# MIMXRT1021 register map
Vendor: nxp.com; File version: 1.0
CPU: CM7 r0p1, little endian, MPU, FPU, VTOR, 4 interrupt priority bits
Registers are 32-bit, read-write, reset 0x0 unless marked. A register's access mark holds for its fields unless they carry their own. Offsets are from the block's base; [hi:lo] are bit positions.

## IOMUXC (part 2 of 3)
Base 0x401F8000; register names take the prefix IOMUXC_
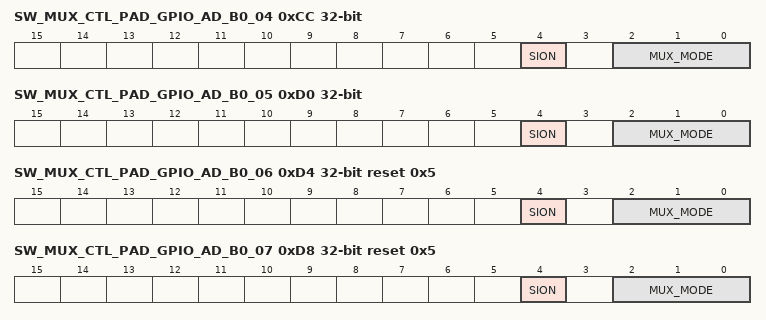
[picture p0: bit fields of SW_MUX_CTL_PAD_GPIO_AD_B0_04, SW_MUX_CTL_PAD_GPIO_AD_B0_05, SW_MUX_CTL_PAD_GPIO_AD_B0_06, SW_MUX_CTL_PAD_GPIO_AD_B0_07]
0xCC SW_MUX_CTL_PAD_GPIO_AD_B0_04 — SW_MUX_CTL_PAD_GPIO_AD_B0_04 SW MUX Control Register
  [4] SION — Software Input On Field.
    0=DISABLED (Input Path is determined by functionality); 1=ENABLED (Force input path of pad GPIO_AD_B0_04)
  [2:0] MUX_MODE — MUX Mode Select Field.
    0=ALT0 (Select mux mode: ALT0 mux port: JTAG_TDO of instance: jtag_mux); 1=ALT1 (Select mux mode: ALT1 mux port: FLEXCAN1_TX of instance: flexcan1); 2=ALT2 (Select mux mode: ALT2 mux port: USDHC1_WP of instance: usdhc1); 3=ALT3 (Select mux mode: ALT3 mux port: QTIMER2_TIMER0 of instance: qtimer2); 4=ALT4 (Select mux mode: ALT4 mux port: ENET_MDIO of instance: enet); 5=ALT5 (Select mux mode: ALT5 mux port: GPIO1_IO04 of instance: gpio1); 6=ALT6 (Select mux mode: ALT6 mux port: USB_OTG1_PWR of instance: usb); 7=ALT7 (Select mux mode: ALT7 mux port: EWM_OUT_B of instance: ewm)
0xD0 SW_MUX_CTL_PAD_GPIO_AD_B0_05 — SW_MUX_CTL_PAD_GPIO_AD_B0_05 SW MUX Control Register
  [4] SION — Software Input On Field.
    0=DISABLED (Input Path is determined by functionality); 1=ENABLED (Force input path of pad GPIO_AD_B0_05)
  [2:0] MUX_MODE — MUX Mode Select Field.
    0=ALT0 (Select mux mode: ALT0 mux port: JTAG_TRSTB of instance: jtag_mux); 1=ALT1 (Select mux mode: ALT1 mux port: FLEXCAN1_RX of instance: flexcan1); 2=ALT2 (Select mux mode: ALT2 mux port: USDHC1_CD_B of instance: usdhc1); 3=ALT3 (Select mux mode: ALT3 mux port: QTIMER2_TIMER1 of instance: qtimer2); 4=ALT4 (Select mux mode: ALT4 mux port: ENET_MDC of instance: enet); 5=ALT5 (Select mux mode: ALT5 mux port: GPIO1_IO05 of instance: gpio1); 6=ALT6 (Select mux mode: ALT6 mux port: USB_OTG1_ID of instance: anatop); 7=ALT7 (Select mux mode: ALT7 mux port: NMI_GLUE_NMI of instance: nmi_glue)
0xD4 SW_MUX_CTL_PAD_GPIO_AD_B0_06 reset 0x5 — SW_MUX_CTL_PAD_GPIO_AD_B0_06 SW MUX Control Register
  [4] SION — Software Input On Field.
    0=DISABLED (Input Path is determined by functionality); 1=ENABLED (Force input path of pad GPIO_AD_B0_06)
  [2:0] MUX_MODE — MUX Mode Select Field.
    0=ALT0 (Select mux mode: ALT0 mux port: PIT_TRIGGER00 of instance: pit); 1=ALT1 (Select mux mode: ALT1 mux port: MQS_RIGHT of instance: mqs); 2=ALT2 (Select mux mode: ALT2 mux port: LPUART1_TX of instance: lpuart1); 3=ALT3 (Select mux mode: ALT3 mux port: QTIMER2_TIMER2 of instance: qtimer2); 4=ALT4 (Select mux mode: ALT4 mux port: FLEXPWM2_PWMA03 of instance: flexpwm2); 5=ALT5 (Select mux mode: ALT5 mux port: GPIO1_IO06 of instance: gpio1); 6=ALT6 (Select mux mode: ALT6 mux port: REF_32K_OUT of instance: anatop)
0xD8 SW_MUX_CTL_PAD_GPIO_AD_B0_07 reset 0x5 — SW_MUX_CTL_PAD_GPIO_AD_B0_07 SW MUX Control Register
  [4] SION — Software Input On Field.
    0=DISABLED (Input Path is determined by functionality); 1=ENABLED (Force input path of pad GPIO_AD_B0_07)
  [2:0] MUX_MODE — MUX Mode Select Field.
    0=ALT0 (Select mux mode: ALT0 mux port: PIT_TRIGGER01 of instance: pit); 1=ALT1 (Select mux mode: ALT1 mux port: MQS_LEFT of instance: mqs); 2=ALT2 (Select mux mode: ALT2 mux port: LPUART1_RX of instance: lpuart1); 3=ALT3 (Select mux mode: ALT3 mux port: QTIMER2_TIMER3 of instance: qtimer2); 4=ALT4 (Select mux mode: ALT4 mux port: FLEXPWM2_PWMB03 of instance: flexpwm2); 5=ALT5 (Select mux mode: ALT5 mux port: GPIO1_IO07 of instance: gpio1); 6=ALT6 (Select mux mode: ALT6 mux port: REF_24M_OUT of instance: anatop)
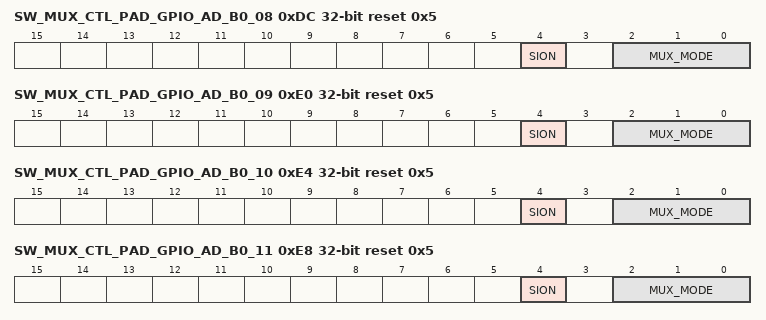
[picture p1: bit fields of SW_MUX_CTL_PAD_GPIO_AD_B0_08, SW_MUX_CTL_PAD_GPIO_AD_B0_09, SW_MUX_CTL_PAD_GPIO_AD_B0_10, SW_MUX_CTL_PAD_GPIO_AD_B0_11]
0xDC SW_MUX_CTL_PAD_GPIO_AD_B0_08 reset 0x5 — SW_MUX_CTL_PAD_GPIO_AD_B0_08 SW MUX Control Register
  [4] SION — Software Input On Field.
    0=DISABLED (Input Path is determined by functionality); 1=ENABLED (Force input path of pad GPIO_AD_B0_08)
  [2:0] MUX_MODE — MUX Mode Select Field.
    0=ALT0 (Select mux mode: ALT0 mux port: ENET_TX_CLK of instance: enet); 1=ALT1 (Select mux mode: ALT1 mux port: LPI2C3_SCL of instance: lpi2c3); 2=ALT2 (Select mux mode: ALT2 mux port: LPUART1_CTS_B of instance: lpuart1); 3=ALT3 (Select mux mode: ALT3 mux port: KPP_COL00 of instance: kpp); 4=ALT4 (Select mux mode: ALT4 mux port: ENET_REF_CLK1 of instance: enet); 5=ALT5 (Select mux mode: ALT5 mux port: GPIO1_IO08 of instance: gpio1); 6=ALT6 (Select mux mode: ALT6 mux port: ARM_CM7_TXEV of instance: cm7_mxrt)
0xE0 SW_MUX_CTL_PAD_GPIO_AD_B0_09 reset 0x5 — SW_MUX_CTL_PAD_GPIO_AD_B0_09 SW MUX Control Register
  [4] SION — Software Input On Field.
    0=DISABLED (Input Path is determined by functionality); 1=ENABLED (Force input path of pad GPIO_AD_B0_09)
  [2:0] MUX_MODE — MUX Mode Select Field.
    0=ALT0 (Select mux mode: ALT0 mux port: ENET_RDATA01 of instance: enet); 1=ALT1 (Select mux mode: ALT1 mux port: LPI2C3_SDA of instance: lpi2c3); 2=ALT2 (Select mux mode: ALT2 mux port: LPUART1_RTS_B of instance: lpuart1); 3=ALT3 (Select mux mode: ALT3 mux port: KPP_ROW00 of instance: kpp); 5=ALT5 (Select mux mode: ALT5 mux port: GPIO1_IO09 of instance: gpio1); 6=ALT6 (Select mux mode: ALT6 mux port: ARM_CM7_RXEV of instance: cm7_mxrt)
0xE4 SW_MUX_CTL_PAD_GPIO_AD_B0_10 reset 0x5 — SW_MUX_CTL_PAD_GPIO_AD_B0_10 SW MUX Control Register
  [4] SION — Software Input On Field.
    0=DISABLED (Input Path is determined by functionality); 1=ENABLED (Force input path of pad GPIO_AD_B0_10)
  [2:0] MUX_MODE — MUX Mode Select Field.
    0=ALT0 (Select mux mode: ALT0 mux port: ENET_RDATA00 of instance: enet); 1=ALT1 (Select mux mode: ALT1 mux port: LPSPI1_SCK of instance: lpspi1); 2=ALT2 (Select mux mode: ALT2 mux port: LPUART5_TX of instance: lpuart5); 3=ALT3 (Select mux mode: ALT3 mux port: KPP_COL01 of instance: kpp); 4=ALT4 (Select mux mode: ALT4 mux port: FLEXPWM2_PWMA02 of instance: flexpwm2); 5=ALT5 (Select mux mode: ALT5 mux port: GPIO1_IO10 of instance: gpio1); 6=ALT6 (Select mux mode: ALT6 mux port: ARM_CM7_TRACE_CLK of instance: cm7_mxrt)
0xE8 SW_MUX_CTL_PAD_GPIO_AD_B0_11 reset 0x5 — SW_MUX_CTL_PAD_GPIO_AD_B0_11 SW MUX Control Register
  [4] SION — Software Input On Field.
    0=DISABLED (Input Path is determined by functionality); 1=ENABLED (Force input path of pad GPIO_AD_B0_11)
  [2:0] MUX_MODE — MUX Mode Select Field.
    0=ALT0 (Select mux mode: ALT0 mux port: ENET_RX_EN of instance: enet); 1=ALT1 (Select mux mode: ALT1 mux port: LPSPI1_PCS0 of instance: lpspi1); 2=ALT2 (Select mux mode: ALT2 mux port: LPUART5_RX of instance: lpuart5); 3=ALT3 (Select mux mode: ALT3 mux port: KPP_ROW01 of instance: kpp); 4=ALT4 (Select mux mode: ALT4 mux port: FLEXPWM2_PWMB02 of instance: flexpwm2); 5=ALT5 (Select mux mode: ALT5 mux port: GPIO1_IO11 of instance: gpio1); 6=ALT6 (Select mux mode: ALT6 mux port: ARM_CM7_TRACE_SWO of instance: cm7_mxrt)
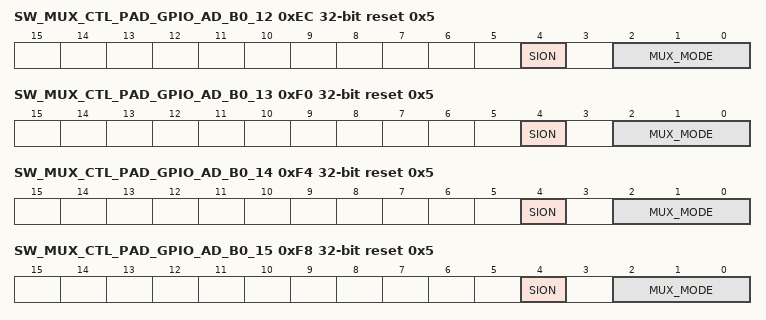
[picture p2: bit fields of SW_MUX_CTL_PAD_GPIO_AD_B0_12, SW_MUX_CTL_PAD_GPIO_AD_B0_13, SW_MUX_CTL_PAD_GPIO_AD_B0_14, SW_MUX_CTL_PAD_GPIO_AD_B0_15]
0xEC SW_MUX_CTL_PAD_GPIO_AD_B0_12 reset 0x5 — SW_MUX_CTL_PAD_GPIO_AD_B0_12 SW MUX Control Register
  [4] SION — Software Input On Field.
    0=DISABLED (Input Path is determined by functionality); 1=ENABLED (Force input path of pad GPIO_AD_B0_12)
  [2:0] MUX_MODE — MUX Mode Select Field.
    0=ALT0 (Select mux mode: ALT0 mux port: ENET_RX_ER of instance: enet); 1=ALT1 (Select mux mode: ALT1 mux port: LPSPI1_SDO of instance: lpspi1); 2=ALT2 (Select mux mode: ALT2 mux port: LPUART3_CTS_B of instance: lpuart3); 3=ALT3 (Select mux mode: ALT3 mux port: KPP_COL02 of instance: kpp); 4=ALT4 (Select mux mode: ALT4 mux port: FLEXPWM2_PWMA01 of instance: flexpwm2); 5=ALT5 (Select mux mode: ALT5 mux port: GPIO1_IO12 of instance: gpio1); 6=ALT6 (Select mux mode: ALT6 mux port: ARM_CM7_TRACE00 of instance: cm7_mxrt); 7=ALT7 (Select mux mode: ALT7 mux port: SNVS_HP_VIO_5_CTL of instance: snvs_hp)
0xF0 SW_MUX_CTL_PAD_GPIO_AD_B0_13 reset 0x5 — SW_MUX_CTL_PAD_GPIO_AD_B0_13 SW MUX Control Register
  [4] SION — Software Input On Field.
    0=DISABLED (Input Path is determined by functionality); 1=ENABLED (Force input path of pad GPIO_AD_B0_13)
  [2:0] MUX_MODE — MUX Mode Select Field.
    0=ALT0 (Select mux mode: ALT0 mux port: ENET_TX_EN of instance: enet); 1=ALT1 (Select mux mode: ALT1 mux port: LPSPI1_SDI of instance: lpspi1); 2=ALT2 (Select mux mode: ALT2 mux port: LPUART3_RTS_B of instance: lpuart3); 3=ALT3 (Select mux mode: ALT3 mux port: KPP_ROW02 of instance: kpp); 4=ALT4 (Select mux mode: ALT4 mux port: FLEXPWM2_PWMB01 of instance: flexpwm2); 5=ALT5 (Select mux mode: ALT5 mux port: GPIO1_IO13 of instance: gpio1); 6=ALT6 (Select mux mode: ALT6 mux port: ARM_CM7_TRACE01 of instance: cm7_mxrt); 7=ALT7 (Select mux mode: ALT7 mux port: SNVS_HP_VIO_5_B of instance: snvs_hp)
0xF4 SW_MUX_CTL_PAD_GPIO_AD_B0_14 reset 0x5 — SW_MUX_CTL_PAD_GPIO_AD_B0_14 SW MUX Control Register
  [4] SION — Software Input On Field.
    0=DISABLED (Input Path is determined by functionality); 1=ENABLED (Force input path of pad GPIO_AD_B0_14)
  [2:0] MUX_MODE — MUX Mode Select Field.
    0=ALT0 (Select mux mode: ALT0 mux port: ENET_TDATA00 of instance: enet); 1=ALT1 (Select mux mode: ALT1 mux port: FLEXCAN2_TX of instance: flexcan2); 2=ALT2 (Select mux mode: ALT2 mux port: LPUART3_TX of instance: lpuart3); 3=ALT3 (Select mux mode: ALT3 mux port: KPP_COL03 of instance: kpp); 4=ALT4 (Select mux mode: ALT4 mux port: FLEXPWM2_PWMA00 of instance: flexpwm2); 5=ALT5 (Select mux mode: ALT5 mux port: GPIO1_IO14 of instance: gpio1); 6=ALT6 (Select mux mode: ALT6 mux port: ARM_CM7_TRACE02 of instance: cm7_mxrt); 7=ALT7 (Select mux mode: ALT7 mux port: WDOG1_ANY of instance: wdog1)
0xF8 SW_MUX_CTL_PAD_GPIO_AD_B0_15 reset 0x5 — SW_MUX_CTL_PAD_GPIO_AD_B0_15 SW MUX Control Register
  [4] SION — Software Input On Field.
    0=DISABLED (Input Path is determined by functionality); 1=ENABLED (Force input path of pad GPIO_AD_B0_15)
  [2:0] MUX_MODE — MUX Mode Select Field.
    0=ALT0 (Select mux mode: ALT0 mux port: ENET_TDATA01 of instance: enet); 1=ALT1 (Select mux mode: ALT1 mux port: FLEXCAN2_RX of instance: flexcan2); 2=ALT2 (Select mux mode: ALT2 mux port: LPUART3_RX of instance: lpuart3); 3=ALT3 (Select mux mode: ALT3 mux port: KPP_ROW03 of instance: kpp); 4=ALT4 (Select mux mode: ALT4 mux port: FLEXPWM2_PWMB00 of instance: flexpwm2); 5=ALT5 (Select mux mode: ALT5 mux port: GPIO1_IO15 of instance: gpio1); 6=ALT6 (Select mux mode: ALT6 mux port: ARM_CM7_TRACE03 of instance: cm7_mxrt)
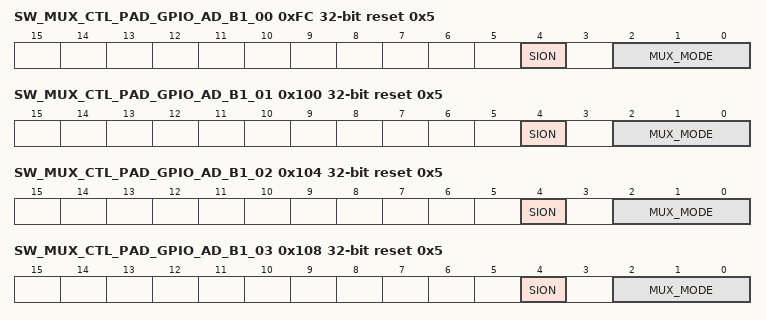
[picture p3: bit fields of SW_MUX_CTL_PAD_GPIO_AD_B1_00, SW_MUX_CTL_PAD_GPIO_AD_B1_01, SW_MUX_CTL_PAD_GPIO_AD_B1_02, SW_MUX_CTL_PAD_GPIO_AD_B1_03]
0xFC SW_MUX_CTL_PAD_GPIO_AD_B1_00 reset 0x5 — SW_MUX_CTL_PAD_GPIO_AD_B1_00 SW MUX Control Register
  [4] SION — Software Input On Field.
    0=DISABLED (Input Path is determined by functionality); 1=ENABLED (Force input path of pad GPIO_AD_B1_00)
  [2:0] MUX_MODE — MUX Mode Select Field.
    0=ALT0 (Select mux mode: ALT0 mux port: SEMC_READY of instance: semc); 1=ALT1 (Select mux mode: ALT1 mux port: FLEXSPI_A_DATA03 of instance: flexspi_bus2bit); 2=ALT2 (Select mux mode: ALT2 mux port: FLEXCAN2_TX of instance: flexcan2); 3=ALT3 (Select mux mode: ALT3 mux port: SAI1_MCLK of instance: sai1); 4=ALT4 (Select mux mode: ALT4 mux port: FLEXIO1_FLEXIO15 of instance: flexio1); 5=ALT5 (Select mux mode: ALT5 mux port: GPIO1_IO16 of instance: gpio1); 6=ALT6 (Select mux mode: ALT6 mux port: ENET_1588_EVENT2_OUT of instance: enet); 7=ALT7 (Select mux mode: ALT7 mux port: KPP_COL04 of instance: kpp)
0x100 SW_MUX_CTL_PAD_GPIO_AD_B1_01 reset 0x5 — SW_MUX_CTL_PAD_GPIO_AD_B1_01 SW MUX Control Register
  [4] SION — Software Input On Field.
    0=DISABLED (Input Path is determined by functionality); 1=ENABLED (Force input path of pad GPIO_AD_B1_01)
  [2:0] MUX_MODE — MUX Mode Select Field.
    0=ALT0 (Select mux mode: ALT0 mux port: SEMC_CSX00 of instance: semc); 1=ALT1 (Select mux mode: ALT1 mux port: FLEXSPI_A_SCLK of instance: flexspi_bus2bit); 2=ALT2 (Select mux mode: ALT2 mux port: FLEXCAN2_RX of instance: flexcan2); 3=ALT3 (Select mux mode: ALT3 mux port: SAI1_TX_BCLK of instance: sai1); 4=ALT4 (Select mux mode: ALT4 mux port: FLEXIO1_FLEXIO14 of instance: flexio1); 5=ALT5 (Select mux mode: ALT5 mux port: GPIO1_IO17 of instance: gpio1); 6=ALT6 (Select mux mode: ALT6 mux port: ENET_1588_EVENT2_IN of instance: enet); 7=ALT7 (Select mux mode: ALT7 mux port: KPP_ROW04 of instance: kpp)
0x104 SW_MUX_CTL_PAD_GPIO_AD_B1_02 reset 0x5 — SW_MUX_CTL_PAD_GPIO_AD_B1_02 SW MUX Control Register
  [4] SION — Software Input On Field.
    0=DISABLED (Input Path is determined by functionality); 1=ENABLED (Force input path of pad GPIO_AD_B1_02)
  [2:0] MUX_MODE — MUX Mode Select Field.
    0=ALT0 (Select mux mode: ALT0 mux port: SEMC_CSX01 of instance: semc); 1=ALT1 (Select mux mode: ALT1 mux port: FLEXSPI_A_DATA00 of instance: flexspi_bus2bit); 2=ALT2 (Select mux mode: ALT2 mux port: LPSPI4_SCK of instance: lpspi4); 3=ALT3 (Select mux mode: ALT3 mux port: SAI1_TX_SYNC of instance: sai1); 4=ALT4 (Select mux mode: ALT4 mux port: FLEXIO1_FLEXIO13 of instance: flexio1); 5=ALT5 (Select mux mode: ALT5 mux port: GPIO1_IO18 of instance: gpio1); 6=ALT6 (Select mux mode: ALT6 mux port: ENET_1588_EVENT3_OUT of instance: enet); 7=ALT7 (Select mux mode: ALT7 mux port: KPP_COL05 of instance: kpp)
0x108 SW_MUX_CTL_PAD_GPIO_AD_B1_03 reset 0x5 — SW_MUX_CTL_PAD_GPIO_AD_B1_03 SW MUX Control Register
  [4] SION — Software Input On Field.
    0=DISABLED (Input Path is determined by functionality); 1=ENABLED (Force input path of pad GPIO_AD_B1_03)
  [2:0] MUX_MODE — MUX Mode Select Field.
    0=ALT0 (Select mux mode: ALT0 mux port: SEMC_CSX02 of instance: semc); 1=ALT1 (Select mux mode: ALT1 mux port: FLEXSPI_A_DATA02 of instance: flexspi_bus2bit); 2=ALT2 (Select mux mode: ALT2 mux port: LPSPI4_PCS0 of instance: lpspi4); 3=ALT3 (Select mux mode: ALT3 mux port: SAI1_TX_DATA00 of instance: sai1); 4=ALT4 (Select mux mode: ALT4 mux port: FLEXIO1_FLEXIO12 of instance: flexio1); 5=ALT5 (Select mux mode: ALT5 mux port: GPIO1_IO19 of instance: gpio1); 6=ALT6 (Select mux mode: ALT6 mux port: ENET_1588_EVENT3_IN of instance: enet); 7=ALT7 (Select mux mode: ALT7 mux port: KPP_ROW05 of instance: kpp)
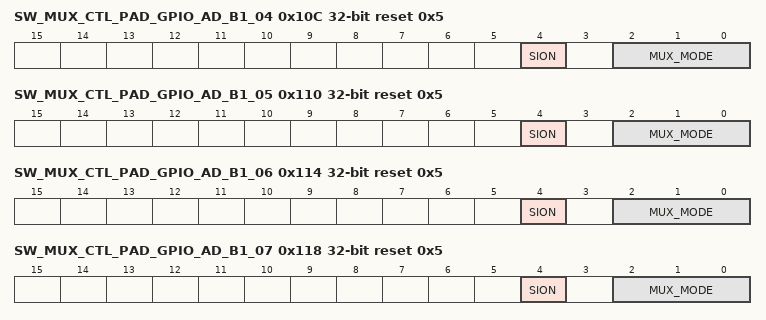
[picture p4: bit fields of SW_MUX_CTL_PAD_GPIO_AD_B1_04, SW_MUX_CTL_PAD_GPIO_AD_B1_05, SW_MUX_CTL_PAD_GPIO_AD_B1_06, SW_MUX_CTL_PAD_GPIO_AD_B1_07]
0x10C SW_MUX_CTL_PAD_GPIO_AD_B1_04 reset 0x5 — SW_MUX_CTL_PAD_GPIO_AD_B1_04 SW MUX Control Register
  [4] SION — Software Input On Field.
    0=DISABLED (Input Path is determined by functionality); 1=ENABLED (Force input path of pad GPIO_AD_B1_04)
  [2:0] MUX_MODE — MUX Mode Select Field.
    0=ALT0 (Select mux mode: ALT0 mux port: SEMC_CSX03 of instance: semc); 1=ALT1 (Select mux mode: ALT1 mux port: FLEXSPI_A_DATA01 of instance: flexspi_bus2bit); 2=ALT2 (Select mux mode: ALT2 mux port: LPSPI4_SDO of instance: lpspi4); 3=ALT3 (Select mux mode: ALT3 mux port: SAI1_RX_SYNC of instance: sai1); 4=ALT4 (Select mux mode: ALT4 mux port: FLEXIO1_FLEXIO11 of instance: flexio1); 5=ALT5 (Select mux mode: ALT5 mux port: GPIO1_IO20 of instance: gpio1); 6=ALT6 (Select mux mode: ALT6 mux port: LPSPI1_PCS1 of instance: lpspi1); 7=ALT7 (Select mux mode: ALT7 mux port: KPP_COL06 of instance: kpp)
0x110 SW_MUX_CTL_PAD_GPIO_AD_B1_05 reset 0x5 — SW_MUX_CTL_PAD_GPIO_AD_B1_05 SW MUX Control Register
  [4] SION — Software Input On Field.
    0=DISABLED (Input Path is determined by functionality); 1=ENABLED (Force input path of pad GPIO_AD_B1_05)
  [2:0] MUX_MODE — MUX Mode Select Field.
    0=ALT0 (Select mux mode: ALT0 mux port: USDHC1_WP of instance: usdhc1); 1=ALT1 (Select mux mode: ALT1 mux port: FLEXSPI_A_SS0_B of instance: flexspi_bus2bit); 2=ALT2 (Select mux mode: ALT2 mux port: LPSPI4_SDI of instance: lpspi4); 3=ALT3 (Select mux mode: ALT3 mux port: SAI1_RX_DATA00 of instance: sai1); 4=ALT4 (Select mux mode: ALT4 mux port: FLEXIO1_FLEXIO10 of instance: flexio1); 5=ALT5 (Select mux mode: ALT5 mux port: GPIO1_IO21 of instance: gpio1); 6=ALT6 (Select mux mode: ALT6 mux port: LPSPI1_PCS2 of instance: lpspi1); 7=ALT7 (Select mux mode: ALT7 mux port: KPP_ROW06 of instance: kpp)
0x114 SW_MUX_CTL_PAD_GPIO_AD_B1_06 reset 0x5 — SW_MUX_CTL_PAD_GPIO_AD_B1_06 SW MUX Control Register
  [4] SION — Software Input On Field.
    0=DISABLED (Input Path is determined by functionality); 1=ENABLED (Force input path of pad GPIO_AD_B1_06)
  [2:0] MUX_MODE — MUX Mode Select Field.
    0=ALT0 (Select mux mode: ALT0 mux port: USDHC1_RESET_B of instance: usdhc1); 1=ALT1 (Select mux mode: ALT1 mux port: FLEXPWM1_PWMA00 of instance: flexpwm1); 2=ALT2 (Select mux mode: ALT2 mux port: LPUART2_CTS_B of instance: lpuart2); 3=ALT3 (Select mux mode: ALT3 mux port: SAI1_RX_BCLK of instance: sai1); 4=ALT4 (Select mux mode: ALT4 mux port: FLEXIO1_FLEXIO09 of instance: flexio1); 5=ALT5 (Select mux mode: ALT5 mux port: GPIO1_IO22 of instance: gpio1); 6=ALT6 (Select mux mode: ALT6 mux port: LPSPI1_PCS3 of instance: lpspi1); 7=ALT7 (Select mux mode: ALT7 mux port: KPP_COL07 of instance: kpp)
0x118 SW_MUX_CTL_PAD_GPIO_AD_B1_07 reset 0x5 — SW_MUX_CTL_PAD_GPIO_AD_B1_07 SW MUX Control Register
  [4] SION — Software Input On Field.
    0=DISABLED (Input Path is determined by functionality); 1=ENABLED (Force input path of pad GPIO_AD_B1_07)
  [2:0] MUX_MODE — MUX Mode Select Field.
    0=ALT0 (Select mux mode: ALT0 mux port: USDHC1_VSELECT of instance: usdhc1); 1=ALT1 (Select mux mode: ALT1 mux port: FLEXPWM1_PWMB00 of instance: flexpwm1); 2=ALT2 (Select mux mode: ALT2 mux port: LPUART2_RTS_B of instance: lpuart2); 3=ALT3 (Select mux mode: ALT3 mux port: SAI1_TX_DATA01 of instance: sai1); 4=ALT4 (Select mux mode: ALT4 mux port: FLEXIO1_FLEXIO08 of instance: flexio1); 5=ALT5 (Select mux mode: ALT5 mux port: GPIO1_IO23 of instance: gpio1); 6=ALT6 (Select mux mode: ALT6 mux port: LPSPI3_PCS3 of instance: lpspi3); 7=ALT7 (Select mux mode: ALT7 mux port: KPP_ROW07 of instance: kpp)
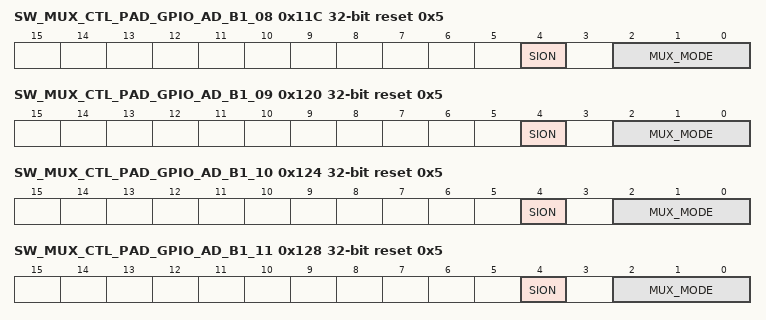
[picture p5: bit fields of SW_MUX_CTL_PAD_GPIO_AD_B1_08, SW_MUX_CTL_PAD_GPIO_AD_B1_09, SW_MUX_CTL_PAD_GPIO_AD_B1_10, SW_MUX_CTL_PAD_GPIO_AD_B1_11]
0x11C SW_MUX_CTL_PAD_GPIO_AD_B1_08 reset 0x5 — SW_MUX_CTL_PAD_GPIO_AD_B1_08 SW MUX Control Register
  [4] SION — Software Input On Field.
    0=DISABLED (Input Path is determined by functionality); 1=ENABLED (Force input path of pad GPIO_AD_B1_08)
  [2:0] MUX_MODE — MUX Mode Select Field.
    0=ALT0 (Select mux mode: ALT0 mux port: LPI2C2_SCL of instance: lpi2c2); 1=ALT1 (Select mux mode: ALT1 mux port: FLEXPWM1_PWMA01 of instance: flexpwm1); 2=ALT2 (Select mux mode: ALT2 mux port: LPUART2_TX of instance: lpuart2); 3=ALT3 (Select mux mode: ALT3 mux port: SAI1_TX_DATA02 of instance: sai1); 4=ALT4 (Select mux mode: ALT4 mux port: FLEXIO1_FLEXIO07 of instance: flexio1); 5=ALT5 (Select mux mode: ALT5 mux port: GPIO1_IO24 of instance: gpio1); 6=ALT6 (Select mux mode: ALT6 mux port: LPSPI3_PCS2 of instance: lpspi3); 7=ALT7 (Select mux mode: ALT7 mux port: XBAR1_INOUT12 of instance: xbar1)
0x120 SW_MUX_CTL_PAD_GPIO_AD_B1_09 reset 0x5 — SW_MUX_CTL_PAD_GPIO_AD_B1_09 SW MUX Control Register
  [4] SION — Software Input On Field.
    0=DISABLED (Input Path is determined by functionality); 1=ENABLED (Force input path of pad GPIO_AD_B1_09)
  [2:0] MUX_MODE — MUX Mode Select Field.
    0=ALT0 (Select mux mode: ALT0 mux port: LPI2C2_SDA of instance: lpi2c2); 1=ALT1 (Select mux mode: ALT1 mux port: FLEXPWM1_PWMB01 of instance: flexpwm1); 2=ALT2 (Select mux mode: ALT2 mux port: LPUART2_RX of instance: lpuart2); 3=ALT3 (Select mux mode: ALT3 mux port: SAI1_TX_DATA03 of instance: sai1); 4=ALT4 (Select mux mode: ALT4 mux port: FLEXIO1_FLEXIO06 of instance: flexio1); 5=ALT5 (Select mux mode: ALT5 mux port: GPIO1_IO25 of instance: gpio1); 6=ALT6 (Select mux mode: ALT6 mux port: LPSPI3_PCS1 of instance: lpspi3); 7=ALT7 (Select mux mode: ALT7 mux port: XBAR1_INOUT13 of instance: xbar1)
0x124 SW_MUX_CTL_PAD_GPIO_AD_B1_10 reset 0x5 — SW_MUX_CTL_PAD_GPIO_AD_B1_10 SW MUX Control Register
  [4] SION — Software Input On Field.
    0=DISABLED (Input Path is determined by functionality); 1=ENABLED (Force input path of pad GPIO_AD_B1_10)
  [2:0] MUX_MODE — MUX Mode Select Field.
    0=ALT0 (Select mux mode: ALT0 mux port: USB_OTG1_PWR of instance: usb); 1=ALT1 (Select mux mode: ALT1 mux port: FLEXPWM1_PWMA02 of instance: flexpwm1); 2=ALT2 (Select mux mode: ALT2 mux port: LPUART4_TX of instance: lpuart4); 3=ALT3 (Select mux mode: ALT3 mux port: USDHC1_CD_B of instance: usdhc1); 4=ALT4 (Select mux mode: ALT4 mux port: FLEXIO1_FLEXIO05 of instance: flexio1); 5=ALT5 (Select mux mode: ALT5 mux port: GPIO1_IO26 of instance: gpio1); 6=ALT6 (Select mux mode: ALT6 mux port: GPT2_CAPTURE1 of instance: gpt2)
0x128 SW_MUX_CTL_PAD_GPIO_AD_B1_11 reset 0x5 — SW_MUX_CTL_PAD_GPIO_AD_B1_11 SW MUX Control Register
  [4] SION — Software Input On Field.
    0=DISABLED (Input Path is determined by functionality); 1=ENABLED (Force input path of pad GPIO_AD_B1_11)
  [2:0] MUX_MODE — MUX Mode Select Field.
    0=ALT0 (Select mux mode: ALT0 mux port: USB_OTG1_ID of instance: anatop); 1=ALT1 (Select mux mode: ALT1 mux port: FLEXPWM1_PWMB02 of instance: flexpwm1); 2=ALT2 (Select mux mode: ALT2 mux port: LPUART4_RX of instance: lpuart4); 3=ALT3 (Select mux mode: ALT3 mux port: USDHC1_WP of instance: usdhc1); 4=ALT4 (Select mux mode: ALT4 mux port: FLEXIO1_FLEXIO04 of instance: flexio1); 5=ALT5 (Select mux mode: ALT5 mux port: GPIO1_IO27 of instance: gpio1); 6=ALT6 (Select mux mode: ALT6 mux port: GPT2_COMPARE1 of instance: gpt2)
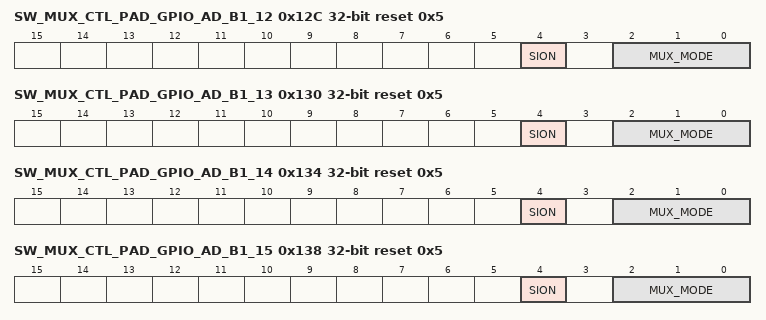
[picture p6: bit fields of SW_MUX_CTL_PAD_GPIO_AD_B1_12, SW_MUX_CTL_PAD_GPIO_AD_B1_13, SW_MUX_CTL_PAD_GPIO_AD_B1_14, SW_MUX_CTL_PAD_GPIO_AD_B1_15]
0x12C SW_MUX_CTL_PAD_GPIO_AD_B1_12 reset 0x5 — SW_MUX_CTL_PAD_GPIO_AD_B1_12 SW MUX Control Register
  [4] SION — Software Input On Field.
    0=DISABLED (Input Path is determined by functionality); 1=ENABLED (Force input path of pad GPIO_AD_B1_12)
  [2:0] MUX_MODE — MUX Mode Select Field.
    0=ALT0 (Select mux mode: ALT0 mux port: USB_OTG1_OC of instance: usb); 1=ALT1 (Select mux mode: ALT1 mux port: ACMP1_OUT of instance: cmp1); 2=ALT2 (Select mux mode: ALT2 mux port: LPSPI3_SCK of instance: lpspi3); 3=ALT3 (Select mux mode: ALT3 mux port: USDHC2_CD_B of instance: usdhc2); 4=ALT4 (Select mux mode: ALT4 mux port: FLEXIO1_FLEXIO03 of instance: flexio1); 5=ALT5 (Select mux mode: ALT5 mux port: GPIO1_IO28 of instance: gpio1); 6=ALT6 (Select mux mode: ALT6 mux port: FLEXPWM1_PWMA03 of instance: flexpwm1)
0x130 SW_MUX_CTL_PAD_GPIO_AD_B1_13 reset 0x5 — SW_MUX_CTL_PAD_GPIO_AD_B1_13 SW MUX Control Register
  [4] SION — Software Input On Field.
    0=DISABLED (Input Path is determined by functionality); 1=ENABLED (Force input path of pad GPIO_AD_B1_13)
  [2:0] MUX_MODE — MUX Mode Select Field.
    0=ALT0 (Select mux mode: ALT0 mux port: LPI2C1_HREQ of instance: lpi2c1); 1=ALT1 (Select mux mode: ALT1 mux port: ACMP2_OUT of instance: cmp2); 2=ALT2 (Select mux mode: ALT2 mux port: LPSPI3_PCS0 of instance: lpspi3); 3=ALT3 (Select mux mode: ALT3 mux port: USDHC2_WP of instance: usdhc2); 4=ALT4 (Select mux mode: ALT4 mux port: FLEXIO1_FLEXIO02 of instance: flexio1); 5=ALT5 (Select mux mode: ALT5 mux port: GPIO1_IO29 of instance: gpio1); 6=ALT6 (Select mux mode: ALT6 mux port: FLEXPWM1_PWMB03 of instance: flexpwm1)
0x134 SW_MUX_CTL_PAD_GPIO_AD_B1_14 reset 0x5 — SW_MUX_CTL_PAD_GPIO_AD_B1_14 SW MUX Control Register
  [4] SION — Software Input On Field.
    0=DISABLED (Input Path is determined by functionality); 1=ENABLED (Force input path of pad GPIO_AD_B1_14)
  [2:0] MUX_MODE — MUX Mode Select Field.
    0=ALT0 (Select mux mode: ALT0 mux port: LPI2C1_SCL of instance: lpi2c1); 1=ALT1 (Select mux mode: ALT1 mux port: ACMP3_OUT of instance: cmp3); 2=ALT2 (Select mux mode: ALT2 mux port: LPSPI3_SDO of instance: lpspi3); 3=ALT3 (Select mux mode: ALT3 mux port: ENET_1588_EVENT0_OUT of instance: enet); 4=ALT4 (Select mux mode: ALT4 mux port: FLEXIO1_FLEXIO01 of instance: flexio1); 5=ALT5 (Select mux mode: ALT5 mux port: GPIO1_IO30 of instance: gpio1)
0x138 SW_MUX_CTL_PAD_GPIO_AD_B1_15 reset 0x5 — SW_MUX_CTL_PAD_GPIO_AD_B1_15 SW MUX Control Register
  [4] SION — Software Input On Field.
    0=DISABLED (Input Path is determined by functionality); 1=ENABLED (Force input path of pad GPIO_AD_B1_15)
  [2:0] MUX_MODE — MUX Mode Select Field.
    0=ALT0 (Select mux mode: ALT0 mux port: LPI2C1_SDA of instance: lpi2c1); 1=ALT1 (Select mux mode: ALT1 mux port: ACMP4_OUT of instance: cmp4); 2=ALT2 (Select mux mode: ALT2 mux port: LPSPI3_SDI of instance: lpspi3); 3=ALT3 (Select mux mode: ALT3 mux port: ENET_1588_EVENT0_IN of instance: enet); 4=ALT4 (Select mux mode: ALT4 mux port: FLEXIO1_FLEXIO00 of instance: flexio1); 5=ALT5 (Select mux mode: ALT5 mux port: GPIO1_IO31 of instance: gpio1)
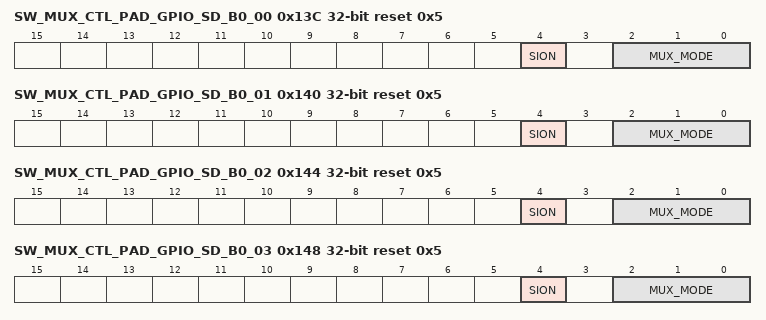
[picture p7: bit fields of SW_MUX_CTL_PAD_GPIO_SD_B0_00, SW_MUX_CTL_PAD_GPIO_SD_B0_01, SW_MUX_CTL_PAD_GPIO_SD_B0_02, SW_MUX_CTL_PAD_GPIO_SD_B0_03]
0x13C SW_MUX_CTL_PAD_GPIO_SD_B0_00 reset 0x5 — SW_MUX_CTL_PAD_GPIO_SD_B0_00 SW MUX Control Register
  [4] SION — Software Input On Field.
    0=DISABLED (Input Path is determined by functionality); 1=ENABLED (Force input path of pad GPIO_SD_B0_00)
  [2:0] MUX_MODE — MUX Mode Select Field.
    0=ALT0 (Select mux mode: ALT0 mux port: USDHC1_DATA2 of instance: usdhc1); 1=ALT1 (Select mux mode: ALT1 mux port: QTIMER1_TIMER0 of instance: qtimer1); 2=ALT2 (Select mux mode: ALT2 mux port: SAI1_MCLK of instance: sai1); 3=ALT3 (Select mux mode: ALT3 mux port: SAI2_MCLK of instance: sai2); 4=ALT4 (Select mux mode: ALT4 mux port: LPI2C3_SCL of instance: lpi2c3); 5=ALT5 (Select mux mode: ALT5 mux port: GPIO3_IO13 of instance: gpio3); 6=ALT6 (Select mux mode: ALT6 mux port: FLEXSPI_A_SS1_B of instance: flexspi_bus2bit); 7=ALT7 (Select mux mode: ALT7 mux port: XBAR1_INOUT14 of instance: xbar1)
0x140 SW_MUX_CTL_PAD_GPIO_SD_B0_01 reset 0x5 — SW_MUX_CTL_PAD_GPIO_SD_B0_01 SW MUX Control Register
  [4] SION — Software Input On Field.
    0=DISABLED (Input Path is determined by functionality); 1=ENABLED (Force input path of pad GPIO_SD_B0_01)
  [2:0] MUX_MODE — MUX Mode Select Field.
    0=ALT0 (Select mux mode: ALT0 mux port: USDHC1_DATA3 of instance: usdhc1); 1=ALT1 (Select mux mode: ALT1 mux port: QTIMER1_TIMER1 of instance: qtimer1); 2=ALT2 (Select mux mode: ALT2 mux port: REF_24M_OUT of instance: anatop); 3=ALT3 (Select mux mode: ALT3 mux port: SAI2_RX_SYNC of instance: sai2); 4=ALT4 (Select mux mode: ALT4 mux port: LPI2C3_SDA of instance: lpi2c3); 5=ALT5 (Select mux mode: ALT5 mux port: GPIO3_IO14 of instance: gpio3); 6=ALT6 (Select mux mode: ALT6 mux port: FLEXSPI_B_SS1_B of instance: flexspi_bus2bit); 7=ALT7 (Select mux mode: ALT7 mux port: XBAR1_INOUT15 of instance: xbar1)
0x144 SW_MUX_CTL_PAD_GPIO_SD_B0_02 reset 0x5 — SW_MUX_CTL_PAD_GPIO_SD_B0_02 SW MUX Control Register
  [4] SION — Software Input On Field.
    0=DISABLED (Input Path is determined by functionality); 1=ENABLED (Force input path of pad GPIO_SD_B0_02)
  [2:0] MUX_MODE — MUX Mode Select Field.
    0=ALT0 (Select mux mode: ALT0 mux port: USDHC1_CMD of instance: usdhc1); 1=ALT1 (Select mux mode: ALT1 mux port: QTIMER1_TIMER2 of instance: qtimer1); 2=ALT2 (Select mux mode: ALT2 mux port: LPUART7_CTS_B of instance: lpuart7); 3=ALT3 (Select mux mode: ALT3 mux port: SAI2_RX_BCLK of instance: sai2); 4=ALT4 (Select mux mode: ALT4 mux port: LPSPI1_SCK of instance: lpspi1); 5=ALT5 (Select mux mode: ALT5 mux port: GPIO3_IO15 of instance: gpio3); 6=ALT6 (Select mux mode: ALT6 mux port: ENET_MDIO of instance: enet); 7=ALT7 (Select mux mode: ALT7 mux port: XBAR1_INOUT16 of instance: xbar1)
0x148 SW_MUX_CTL_PAD_GPIO_SD_B0_03 reset 0x5 — SW_MUX_CTL_PAD_GPIO_SD_B0_03 SW MUX Control Register
  [4] SION — Software Input On Field.
    0=DISABLED (Input Path is determined by functionality); 1=ENABLED (Force input path of pad GPIO_SD_B0_03)
  [2:0] MUX_MODE — MUX Mode Select Field.
    0=ALT0 (Select mux mode: ALT0 mux port: USDHC1_CLK of instance: usdhc1); 1=ALT1 (Select mux mode: ALT1 mux port: QTIMER1_TIMER3 of instance: qtimer1); 2=ALT2 (Select mux mode: ALT2 mux port: LPUART7_RTS_B of instance: lpuart7); 3=ALT3 (Select mux mode: ALT3 mux port: SAI2_RX_DATA of instance: sai2); 4=ALT4 (Select mux mode: ALT4 mux port: LPSPI1_PCS0 of instance: lpspi1); 5=ALT5 (Select mux mode: ALT5 mux port: GPIO3_IO16 of instance: gpio3); 6=ALT6 (Select mux mode: ALT6 mux port: ENET_MDC of instance: enet)
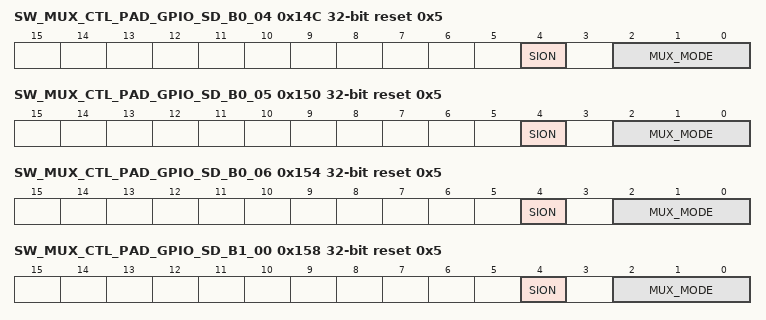
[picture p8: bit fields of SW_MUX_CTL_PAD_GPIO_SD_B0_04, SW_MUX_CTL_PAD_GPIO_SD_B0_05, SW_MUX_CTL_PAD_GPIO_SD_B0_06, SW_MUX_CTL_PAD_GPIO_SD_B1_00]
0x14C SW_MUX_CTL_PAD_GPIO_SD_B0_04 reset 0x5 — SW_MUX_CTL_PAD_GPIO_SD_B0_04 SW MUX Control Register
  [4] SION — Software Input On Field.
    0=DISABLED (Input Path is determined by functionality); 1=ENABLED (Force input path of pad GPIO_SD_B0_04)
  [2:0] MUX_MODE — MUX Mode Select Field.
    0=ALT0 (Select mux mode: ALT0 mux port: USDHC1_DATA0 of instance: usdhc1); 1=ALT1 (Select mux mode: ALT1 mux port: FLEXCAN2_TX of instance: flexcan2); 2=ALT2 (Select mux mode: ALT2 mux port: LPUART7_TX of instance: lpuart7); 3=ALT3 (Select mux mode: ALT3 mux port: SAI2_TX_DATA of instance: sai2); 4=ALT4 (Select mux mode: ALT4 mux port: LPSPI1_SDO of instance: lpspi1); 5=ALT5 (Select mux mode: ALT5 mux port: GPIO3_IO17 of instance: gpio3); 6=ALT6 (Select mux mode: ALT6 mux port: FLEXSPI_B_SS0_B of instance: flexspi_bus2bit)
0x150 SW_MUX_CTL_PAD_GPIO_SD_B0_05 reset 0x5 — SW_MUX_CTL_PAD_GPIO_SD_B0_05 SW MUX Control Register
  [4] SION — Software Input On Field.
    0=DISABLED (Input Path is determined by functionality); 1=ENABLED (Force input path of pad GPIO_SD_B0_05)
  [2:0] MUX_MODE — MUX Mode Select Field.
    0=ALT0 (Select mux mode: ALT0 mux port: USDHC1_DATA1 of instance: usdhc1); 1=ALT1 (Select mux mode: ALT1 mux port: FLEXCAN2_RX of instance: flexcan2); 2=ALT2 (Select mux mode: ALT2 mux port: LPUART7_RX of instance: lpuart7); 3=ALT3 (Select mux mode: ALT3 mux port: SAI2_TX_BCLK of instance: sai2); 4=ALT4 (Select mux mode: ALT4 mux port: LPSPI1_SDI of instance: lpspi1); 5=ALT5 (Select mux mode: ALT5 mux port: GPIO3_IO18 of instance: gpio3); 6=ALT6 (Select mux mode: ALT6 mux port: FLEXSPI_B_DQS of instance: flexspi_bus2bit)
0x154 SW_MUX_CTL_PAD_GPIO_SD_B0_06 reset 0x5 — SW_MUX_CTL_PAD_GPIO_SD_B0_06 SW MUX Control Register
  [4] SION — Software Input On Field.
    0=DISABLED (Input Path is determined by functionality); 1=ENABLED (Force input path of pad GPIO_SD_B0_06)
  [2:0] MUX_MODE — MUX Mode Select Field.
    0=ALT0 (Select mux mode: ALT0 mux port: USDHC1_CD_B of instance: usdhc1); 1=ALT1 (Select mux mode: ALT1 mux port: USDHC1_RESET_B of instance: usdhc1); 2=ALT2 (Select mux mode: ALT2 mux port: REF_32K_OUT of instance: anatop); 3=ALT3 (Select mux mode: ALT3 mux port: SAI2_TX_SYNC of instance: sai2); 4=ALT4 (Select mux mode: ALT4 mux port: WDOG1_B of instance: wdog1); 5=ALT5 (Select mux mode: ALT5 mux port: GPIO3_IO19 of instance: gpio3); 6=ALT6 (Select mux mode: ALT6 mux port: XBAR1_INOUT17 of instance: xbar1)
0x158 SW_MUX_CTL_PAD_GPIO_SD_B1_00 reset 0x5 — SW_MUX_CTL_PAD_GPIO_SD_B1_00 SW MUX Control Register
  [4] SION — Software Input On Field.
    0=DISABLED (Input Path is determined by functionality); 1=ENABLED (Force input path of pad GPIO_SD_B1_00)
  [2:0] MUX_MODE — MUX Mode Select Field.
    0=ALT0 (Select mux mode: ALT0 mux port: USDHC2_DATA2 of instance: usdhc2); 1=ALT1 (Select mux mode: ALT1 mux port: FLEXSPI_B_DATA03 of instance: flexspi_bus2bit); 2=ALT2 (Select mux mode: ALT2 mux port: LPUART6_TX of instance: lpuart6); 3=ALT3 (Select mux mode: ALT3 mux port: XBAR1_INOUT10 of instance: xbar1); 4=ALT4 (Select mux mode: ALT4 mux port: FLEXCAN1_TX of instance: flexcan1); 5=ALT5 (Select mux mode: ALT5 mux port: GPIO3_IO20 of instance: gpio3)
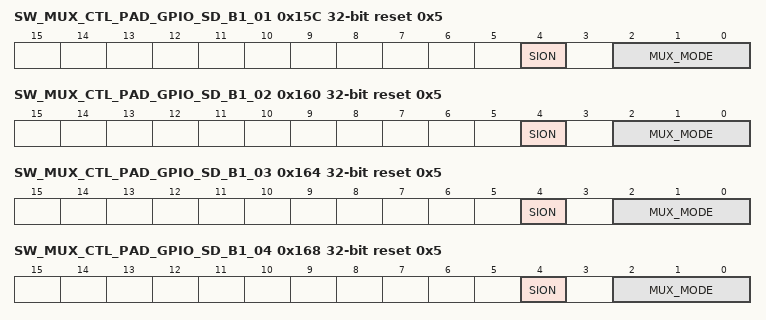
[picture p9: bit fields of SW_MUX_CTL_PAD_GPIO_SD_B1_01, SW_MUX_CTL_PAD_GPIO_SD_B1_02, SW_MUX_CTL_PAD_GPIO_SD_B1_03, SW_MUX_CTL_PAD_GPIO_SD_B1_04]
0x15C SW_MUX_CTL_PAD_GPIO_SD_B1_01 reset 0x5 — SW_MUX_CTL_PAD_GPIO_SD_B1_01 SW MUX Control Register
  [4] SION — Software Input On Field.
    0=DISABLED (Input Path is determined by functionality); 1=ENABLED (Force input path of pad GPIO_SD_B1_01)
  [2:0] MUX_MODE — MUX Mode Select Field.
    0=ALT0 (Select mux mode: ALT0 mux port: USDHC2_DATA3 of instance: usdhc2); 1=ALT1 (Select mux mode: ALT1 mux port: FLEXSPI_B_SCLK of instance: flexspi_bus2bit); 2=ALT2 (Select mux mode: ALT2 mux port: LPUART6_RX of instance: lpuart6); 3=ALT3 (Select mux mode: ALT3 mux port: FLEXSPI_A_SS1_B of instance: flexspi_bus2bit); 4=ALT4 (Select mux mode: ALT4 mux port: FLEXCAN1_RX of instance: flexcan1); 5=ALT5 (Select mux mode: ALT5 mux port: GPIO3_IO21 of instance: gpio3)
0x160 SW_MUX_CTL_PAD_GPIO_SD_B1_02 reset 0x5 — SW_MUX_CTL_PAD_GPIO_SD_B1_02 SW MUX Control Register
  [4] SION — Software Input On Field.
    0=DISABLED (Input Path is determined by functionality); 1=ENABLED (Force input path of pad GPIO_SD_B1_02)
  [2:0] MUX_MODE — MUX Mode Select Field.
    0=ALT0 (Select mux mode: ALT0 mux port: USDHC2_CMD of instance: usdhc2); 1=ALT1 (Select mux mode: ALT1 mux port: FLEXSPI_B_DATA00 of instance: flexspi_bus2bit); 2=ALT2 (Select mux mode: ALT2 mux port: LPUART8_TX of instance: lpuart8); 3=ALT3 (Select mux mode: ALT3 mux port: LPI2C4_SCL of instance: lpi2c4); 4=ALT4 (Select mux mode: ALT4 mux port: ENET_1588_EVENT1_OUT of instance: enet); 5=ALT5 (Select mux mode: ALT5 mux port: GPIO3_IO22 of instance: gpio3); 6=ALT6 (Select mux mode: ALT6 mux port: CCM_CLKO1 of instance: ccm)
0x164 SW_MUX_CTL_PAD_GPIO_SD_B1_03 reset 0x5 — SW_MUX_CTL_PAD_GPIO_SD_B1_03 SW MUX Control Register
  [4] SION — Software Input On Field.
    0=DISABLED (Input Path is determined by functionality); 1=ENABLED (Force input path of pad GPIO_SD_B1_03)
  [2:0] MUX_MODE — MUX Mode Select Field.
    0=ALT0 (Select mux mode: ALT0 mux port: USDHC2_CLK of instance: usdhc2); 1=ALT1 (Select mux mode: ALT1 mux port: FLEXSPI_B_DATA02 of instance: flexspi_bus2bit); 2=ALT2 (Select mux mode: ALT2 mux port: LPUART8_RX of instance: lpuart8); 3=ALT3 (Select mux mode: ALT3 mux port: LPI2C4_SDA of instance: lpi2c4); 4=ALT4 (Select mux mode: ALT4 mux port: ENET_1588_EVENT1_IN of instance: enet); 5=ALT5 (Select mux mode: ALT5 mux port: GPIO3_IO23 of instance: gpio3); 6=ALT6 (Select mux mode: ALT6 mux port: CCM_CLKO2 of instance: ccm)
0x168 SW_MUX_CTL_PAD_GPIO_SD_B1_04 reset 0x5 — SW_MUX_CTL_PAD_GPIO_SD_B1_04 SW MUX Control Register
  [4] SION — Software Input On Field.
    0=DISABLED (Input Path is determined by functionality); 1=ENABLED (Force input path of pad GPIO_SD_B1_04)
  [2:0] MUX_MODE — MUX Mode Select Field.
    0=ALT0 (Select mux mode: ALT0 mux port: USDHC2_DATA0 of instance: usdhc2); 1=ALT1 (Select mux mode: ALT1 mux port: FLEXSPI_B_DATA01 of instance: flexspi_bus2bit); 2=ALT2 (Select mux mode: ALT2 mux port: ENET_TX_CLK of instance: enet); 3=ALT3 (Select mux mode: ALT3 mux port: ENET_REF_CLK1 of instance: enet); 4=ALT4 (Select mux mode: ALT4 mux port: EWM_OUT_B of instance: ewm); 5=ALT5 (Select mux mode: ALT5 mux port: GPIO3_IO24 of instance: gpio3); 6=ALT6 (Select mux mode: ALT6 mux port: CCM_WAIT of instance: ccm)
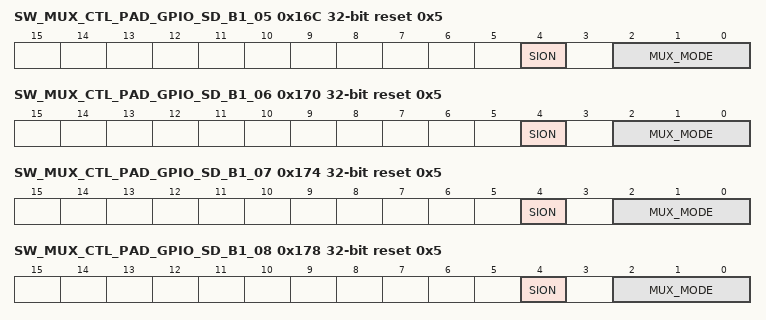
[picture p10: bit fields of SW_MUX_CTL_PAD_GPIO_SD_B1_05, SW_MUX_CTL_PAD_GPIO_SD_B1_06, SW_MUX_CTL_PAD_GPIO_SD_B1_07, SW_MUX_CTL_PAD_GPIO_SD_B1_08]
0x16C SW_MUX_CTL_PAD_GPIO_SD_B1_05 reset 0x5 — SW_MUX_CTL_PAD_GPIO_SD_B1_05 SW MUX Control Register
  [4] SION — Software Input On Field.
    0=DISABLED (Input Path is determined by functionality); 1=ENABLED (Force input path of pad GPIO_SD_B1_05)
  [2:0] MUX_MODE — MUX Mode Select Field.
    0=ALT0 (Select mux mode: ALT0 mux port: USDHC2_DATA1 of instance: usdhc2); 1=ALT1 (Select mux mode: ALT1 mux port: FLEXSPI_A_DQS of instance: flexspi_bus2bit); 2=ALT2 (Select mux mode: ALT2 mux port: ENET_RDATA01 of instance: enet); 3=ALT3 (Select mux mode: ALT3 mux port: SAI3_MCLK of instance: sai3); 4=ALT4 (Select mux mode: ALT4 mux port: FLEXSPI_B_SS0_B of instance: flexspi_bus2bit); 5=ALT5 (Select mux mode: ALT5 mux port: GPIO3_IO25 of instance: gpio3); 6=ALT6 (Select mux mode: ALT6 mux port: CCM_PMIC_RDY of instance: ccm)
0x170 SW_MUX_CTL_PAD_GPIO_SD_B1_06 reset 0x5 — SW_MUX_CTL_PAD_GPIO_SD_B1_06 SW MUX Control Register
  [4] SION — Software Input On Field.
    0=DISABLED (Input Path is determined by functionality); 1=ENABLED (Force input path of pad GPIO_SD_B1_06)
  [2:0] MUX_MODE — MUX Mode Select Field.
    0=ALT0 (Select mux mode: ALT0 mux port: USDHC2_CD_B of instance: usdhc2); 1=ALT1 (Select mux mode: ALT1 mux port: FLEXSPI_A_DATA03 of instance: flexspi_bus2bit); 2=ALT2 (Select mux mode: ALT2 mux port: ENET_RDATA00 of instance: enet); 3=ALT3 (Select mux mode: ALT3 mux port: SAI3_TX_BCLK of instance: sai3); 4=ALT4 (Select mux mode: ALT4 mux port: LPSPI2_PCS0 of instance: lpspi2); 5=ALT5 (Select mux mode: ALT5 mux port: GPIO3_IO26 of instance: gpio3); 6=ALT6 (Select mux mode: ALT6 mux port: CCM_STOP of instance: ccm)
0x174 SW_MUX_CTL_PAD_GPIO_SD_B1_07 reset 0x5 — SW_MUX_CTL_PAD_GPIO_SD_B1_07 SW MUX Control Register
  [4] SION — Software Input On Field.
    0=DISABLED (Input Path is determined by functionality); 1=ENABLED (Force input path of pad GPIO_SD_B1_07)
  [2:0] MUX_MODE — MUX Mode Select Field.
    0=ALT0 (Select mux mode: ALT0 mux port: USDHC2_RESET_B of instance: usdhc2); 1=ALT1 (Select mux mode: ALT1 mux port: FLEXSPI_A_SCLK of instance: flexspi_bus2bit); 2=ALT2 (Select mux mode: ALT2 mux port: ENET_RX_EN of instance: enet); 3=ALT3 (Select mux mode: ALT3 mux port: SAI3_TX_SYNC of instance: sai3); 4=ALT4 (Select mux mode: ALT4 mux port: LPSPI2_SCK of instance: lpspi2); 5=ALT5 (Select mux mode: ALT5 mux port: GPIO3_IO27 of instance: gpio3)
0x178 SW_MUX_CTL_PAD_GPIO_SD_B1_08 reset 0x5 — SW_MUX_CTL_PAD_GPIO_SD_B1_08 SW MUX Control Register
  [4] SION — Software Input On Field.
    0=DISABLED (Input Path is determined by functionality); 1=ENABLED (Force input path of pad GPIO_SD_B1_08)
  [2:0] MUX_MODE — MUX Mode Select Field.
    0=ALT0 (Select mux mode: ALT0 mux port: USDHC2_DATA4 of instance: usdhc2); 1=ALT1 (Select mux mode: ALT1 mux port: FLEXSPI_A_DATA00 of instance: flexspi_bus2bit); 2=ALT2 (Select mux mode: ALT2 mux port: ENET_RX_ER of instance: enet); 3=ALT3 (Select mux mode: ALT3 mux port: SAI3_TX_DATA of instance: sai3); 4=ALT4 (Select mux mode: ALT4 mux port: LPSPI2_SDO of instance: lpspi2); 5=ALT5 (Select mux mode: ALT5 mux port: GPIO3_IO28 of instance: gpio3)
